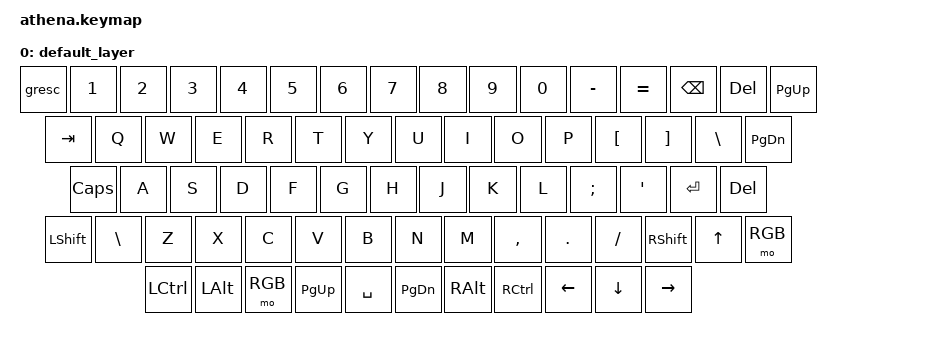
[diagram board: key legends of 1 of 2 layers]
#include <behaviors.dtsi>
#include <dt-bindings/zmk/bt.h>
#include <dt-bindings/zmk/keys.h>
#include <dt-bindings/zmk/rgb.h>

// Layers
#define DEFAULT 0
#define RGB     1

/ {
    keymap {
        compatible = "zmk,keymap";
         sensor-bindings = <&inc_dec_kp C_VOL_UP C_VOL_DN>, <&inc_dec_kp &rgb_ug RGB_BRI &rgb_ug RGB_BRD>;

        default_layer {
            // ------------------------------------------------------------------------------------------------------------------------
            // | ESC |  1  |  2  |  3  |  4  |  5  |  6  |  7  |  8  |  9  |  0  |  -  |  =  | BSPC|DEL|                    |  PG_UP  |
            // | TAB  |  Q  |  W  |  E  |  R  |  T  |  Y  |  U  |  I  |  O  |  P  |  [  |  ]  |   \                         |  PG_DN  |
            // | CAPS  |  A  |  S  |  D  |  F  |  G  |  H  |  J  |  K  |  L  |  ;  |  '  |     ENTER                        |  DEL    |
            // |SHIFT|\|  Z  |  X  |  C  |  V  |  B  |  N  |  M  |  ,  |  .  |  /  |     SHIFT           |   UP   |         |  HOME   |
            // |  CTL  |  WIN  |  ALT  |  PG_UP  |      SPACE        |  PG_DN  |  ALT  |  CTRL  |  LEFT  |  DOWN  |  RIGHT  
            // ------------------------------------------------------------------------------------------------------------------------

            bindings = <
&gresc    &kp N1     &kp N2  &kp N3   &kp N4    &kp N5  &kp N6   &kp N7   &kp N8    &kp N9   &kp N0    &kp MINUS &kp EQUAL &kp BSPC &kp DEL        &kp PG_UP
&kp TAB   &kp Q      &kp W    &kp E    &kp R     &kp T   &kp Y    &kp U    &kp I     &kp O    &kp P     &kp LBKT  &kp RBKT  &kp BSLH                &kp PG_DN  
&kp CLCK  &kp A      &kp S    &kp D    &kp F     &kp G   &kp H    &kp J    &kp K     &kp L    &kp SEMI  &kp SQT             &kp RET                 &kp DEL
&kp LSHFT &kp BSLH   &kp Z    &kp X    &kp C     &kp V   &kp B    &kp N    &kp M     &kp COMMA &kp DOT  &kp FSLH  &kp RSHFT  &kp UP                 &mo RGB
&kp LCTRL &kp LALT   &mo RGB          &kp PG_UP         &kp SPACE         &kp PG_DN           &kp RALT  &kp RCTRL &kp LEFT  &kp DOWN  &kp RIGHT            
            >;

            sensor-bindings = <&inc_dec_kp C_VOL_UP C_VOL_DN>;
        };

        rgb_layer {
            // --------------------------------------------------------------------------------------------------------
            // | BT CLR | F1  | F2  | F3  | F4  | F5  | F6  | F7  | F8  | F9  | F10  | F11 | F12 | EFFECT REV |  DEL  |
            // |  BT 1   |   |  UP |   | HUEUP | SATUP | BRIUP | SPDUP |   |     |    |     |     |           |  INS  |
            // |   BT 2   | LT |  DN  | RT | HUEDN | SATDN | BRIDN | SPDDN |   |     |   |     |  EFFECT FORW | PSCRN |
            // |    BT 3     |     |      |      |     |     |     |     |     |     |     |                  |  END  |
            // |   BT 4  |      |  STUDIO UNLOCK  |             TOG RGB                | PRT SCR |       |       |  DEL |
            // --------------------------------------------------------------------------------------------------------

            bindings = <
&bt BT_CLR    &studio_unlock      &kp F2      &kp F3      &kp F4            &kp F5            &kp F6            &kp F7            &kp F8  &kp F9  &kp F10     &kp F11           &kp F12            &rgb_ug RGB_EFR  &bt BT_SEL 0  
&bt BT_SEL 0  &trans      &bt BT_NXT      &trans      &rgb_ug RGB_HUI   &rgb_ug RGB_SAI   &rgb_ug RGB_BRI   &rgb_ug RGB_SPI   &trans  &trans  &trans      &trans            &trans             &kp INS          &kp INS  
&bt BT_SEL 1      &bt BT_PRV       &rgb_ug RGB_HUD   &rgb_ug RGB_SAD   &rgb_ug RGB_BRD   &rgb_ug RGB_SPD   &trans  &trans  &trans      &rgb_ug RGB_EFF   &kp PSCRN                          &kp PSCRN
&bt BT_SEL 2  &trans      &trans      &trans      &trans            &trans            &trans            &trans            &trans  &trans  &trans      &trans                                                &kp END  
&bt BT_SEL 3  &trans      &trans                  &trans                              &rgb_ug RGB_TOG                              &trans  &trans      &trans            &kp DOWN           &kp C_MUTE
            >;

            sensor-bindings = <&inc_dec_kp C_VOL_UP C_VOL_DN>;
        };
        
        // Add reserved layers for ZMK Studio to use
        extra_layer_1 {       
            status = "reserved";
        };
        
        extra_layer_2 {
            status = "reserved";
        };
    };
};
